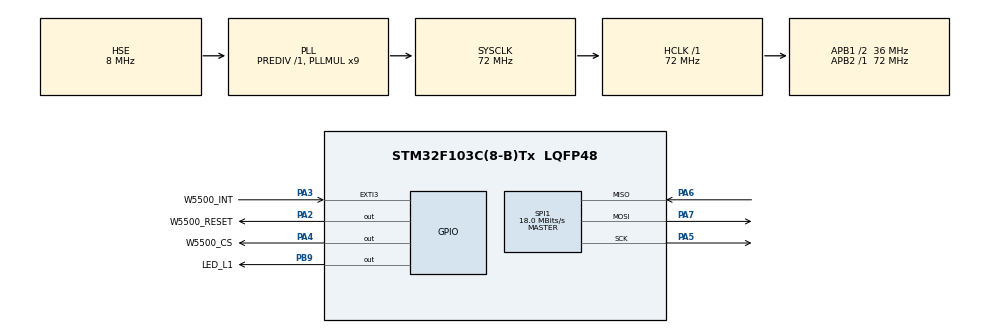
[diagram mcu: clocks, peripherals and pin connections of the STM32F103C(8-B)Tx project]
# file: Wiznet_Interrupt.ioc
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Mcu.Family=STM32F1
Mcu.Name=STM32F103C(8-B)Tx
Mcu.Package=LQFP48
NVIC.EXTI3_IRQn=true\:0\:0\:false\:false\:true\:true\:true\:true
NVIC.PriorityGroup=NVIC_PRIORITYGROUP_4
NVIC.SPI1_IRQn=true\:0\:0\:false\:false\:true\:true\:true\:true
PA13.Mode=Serial_Wire
PA13.Signal=SYS_JTMS-SWDIO
PA14.Mode=Serial_Wire
PA14.Signal=SYS_JTCK-SWCLK
PA2.GPIO_Label=W5500_RESET
PA2.Signal=GPIO_Output
PA3.GPIO_Label=W5500_INT
PA3.GPIO_ModeDefaultEXTI=GPIO_MODE_IT_FALLING
PA3.GPIO_PuPd=GPIO_PULLUP
PA3.Signal=GPXTI3
PA4.GPIO_Label=W5500_CS
PA4.Signal=GPIO_Output
PA5.Mode=Full_Duplex_Master
PA5.Signal=SPI1_SCK
PA6.Mode=Full_Duplex_Master
PA6.Signal=SPI1_MISO
PA7.Mode=Full_Duplex_Master
PA7.Signal=SPI1_MOSI
PB9.GPIO_Label=LED_L1
PB9.PinState=GPIO_PIN_SET
PB9.Signal=GPIO_Output
PD0-OSC_IN.Mode=HSE-External-Oscillator
PD0-OSC_IN.Signal=RCC_OSC_IN
PD1-OSC_OUT.Mode=HSE-External-Oscillator
PD1-OSC_OUT.Signal=RCC_OSC_OUT
ProjectManager.HeapSize=0x200
ProjectManager.StackSize=0x400
ProjectManager.TargetToolchain=STM32CubeIDE
RCC.AHBFreq_Value=72000000
RCC.APB1CLKDivider=RCC_HCLK_DIV2
RCC.APB1Freq_Value=36000000
RCC.APB1TimFreq_Value=72000000
RCC.APB2Freq_Value=72000000
RCC.APB2TimFreq_Value=72000000
RCC.HCLKFreq_Value=72000000
RCC.PLLMUL=RCC_PLL_MUL9
RCC.PLLSourceVirtual=RCC_PLLSOURCE_HSE
RCC.SYSCLKFreq_VALUE=72000000
RCC.SYSCLKSource=RCC_SYSCLKSOURCE_PLLCLK
RCC.USBFreq_Value=48000000
RCC.USBPrescaler=RCC_USBCLKSOURCE_PLL_DIV1_5
SPI1.BaudRatePrescaler=SPI_BAUDRATEPRESCALER_4
SPI1.CalculateBaudRate=18.0 MBits/s
SPI1.Direction=SPI_DIRECTION_2LINES
SPI1.Mode=SPI_MODE_MASTER
SPI1.VirtualType=VM_MASTER
board=custom

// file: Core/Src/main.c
/* USER CODE BEGIN Header */
/**
  ******************************************************************************
  * @file           : main.c
  * @brief          : Main program body
  ******************************************************************************
  * @attention
  *
  * Copyright (c) 2025 STMicroelectronics.
  * All rights reserved.
  *
  * This software is licensed under terms that can be found in the LICENSE file
  * in the root directory of this software component.
  * If no LICENSE file comes with this software, it is provided AS-IS.
  *
  ******************************************************************************
  */
/* USER CODE END Header */
#include "main.h"

SPI_HandleTypeDef hspi1;

/* USER CODE BEGIN PV */
//char sendBuffer[128];// Data holder
wiz_NetInfo netInfo = { .mac = { 0x00, 0x08, 0xdc, 0xab, 0xcd, 0xef }, .ip = {
	  		192, 168, 20, 14 }, .sn = { 255, 255, 255, 0 }, .gw = { 192, 168, 20, 1 },
	  		.dns = { 8, 8, 8, 8 }, .dhcp = NETINFO_STATIC };
uint8_t rrr = 0;
/* USER CODE END PV */

void SystemClock_Config(void);
static void MX_GPIO_Init(void);
static void MX_SPI1_Init(void);

int main(void)
{

  /* MCU Configuration--------------------------------------------------------*/

  /* Reset of all peripherals, Initializes the Flash interface and the Systick. */
  HAL_Init();

  /* Configure the system clock */
  SystemClock_Config();

  /* Initialize all configured peripherals */
  MX_GPIO_Init();
  MX_SPI1_Init();
  /* USER CODE BEGIN 2 */
//  HAL_GPIO_WritePin(LED_L1_GPIO_Port, LED_L1_Pin, SET);
  W5500Init();

  /* USER CODE END 2 */

  /* Infinite loop */
  /* USER CODE BEGIN WHILE */
  while (1)
  {

		W5500_Handle_Events();
//1
		// Send Data to PC
//		for (int socket_no = 0; socket_no < MAX_SOCK_NUM; socket_no++){
//		const char* message1 = "Hello World\r\n";
////		send(socket_no, (uint8_t*)message1, strlen(message1));
//		SendToSocket(socket_no, message1);
//		HAL_Delay(100);
//		}
//2
//		for (int socket_no = 0; socket_no < MAX_SOCK_NUM; socket_no++){
//		// Receive Data from PC and confirm the received Data by sending another message to PC
//		if (strncmp((char*)recv_buf[socket_no], "Hello", 5) == 0) {
//			memset(&recv_buf[socket_no], 0, sizeof(recv_buf[socket_no]));
////			const char* message2 = "Received\r\n";
////			send(socket_no, (uint8_t*)message2, strlen(message2));
//
//			snprintf(sendBuffer, sizeof(sendBuffer), "Received from %d\r\n", socket_no);
//			 send(socket_no, (uint8_t*)sendBuffer, strlen(sendBuffer));
//			HAL_GPIO_TogglePin(LED_L1_GPIO_Port, LED_L1_Pin);
//		}
//		}

//3

//		if (strncmp((char*)recv_buf[0], "Hello", 5) == 0) {
//			memset(&recv_buf[0], 0, sizeof(recv_buf[0]));
//			const char* message2 = "Received\r\n";
////			rrr = send(0, (uint8_t*)message2, strlen(message2));
//
////			SendToSocket(0, message2);
//			HAL_GPIO_TogglePin(LED_L1_GPIO_Port, LED_L1_Pin);
//		}

//	  HAL_Delay(1000);
}

    /* USER CODE END WHILE */

}

void SystemClock_Config(void)
{
  RCC_OscInitTypeDef RCC_OscInitStruct = {0};
  RCC_ClkInitTypeDef RCC_ClkInitStruct = {0};

  /** Initializes the RCC Oscillators according to the specified parameters
  * in the RCC_OscInitTypeDef structure.
  */
  RCC_OscInitStruct.OscillatorType = RCC_OSCILLATORTYPE_HSE;
  RCC_OscInitStruct.HSEState = RCC_HSE_ON;
  RCC_OscInitStruct.HSEPredivValue = RCC_HSE_PREDIV_DIV1;
  RCC_OscInitStruct.HSIState = RCC_HSI_ON;
  RCC_OscInitStruct.PLL.PLLState = RCC_PLL_ON;
  RCC_OscInitStruct.PLL.PLLSource = RCC_PLLSOURCE_HSE;
  RCC_OscInitStruct.PLL.PLLMUL = RCC_PLL_MUL9;
  if (HAL_RCC_OscConfig(&RCC_OscInitStruct) != HAL_OK)
  {
    Error_Handler();
  }

  /** Initializes the CPU, AHB and APB buses clocks
  */
  RCC_ClkInitStruct.ClockType = RCC_CLOCKTYPE_HCLK|RCC_CLOCKTYPE_SYSCLK
                              |RCC_CLOCKTYPE_PCLK1|RCC_CLOCKTYPE_PCLK2;
  RCC_ClkInitStruct.SYSCLKSource = RCC_SYSCLKSOURCE_PLLCLK;
  RCC_ClkInitStruct.AHBCLKDivider = RCC_SYSCLK_DIV1;
  RCC_ClkInitStruct.APB1CLKDivider = RCC_HCLK_DIV2;
  RCC_ClkInitStruct.APB2CLKDivider = RCC_HCLK_DIV1;

  if (HAL_RCC_ClockConfig(&RCC_ClkInitStruct, FLASH_LATENCY_2) != HAL_OK)
  {
    Error_Handler();
  }
}

static void MX_SPI1_Init(void)
{

  /* SPI1 parameter configuration*/
  hspi1.Instance = SPI1;
  hspi1.Init.Mode = SPI_MODE_MASTER;
  hspi1.Init.Direction = SPI_DIRECTION_2LINES;
  hspi1.Init.DataSize = SPI_DATASIZE_8BIT;
  hspi1.Init.CLKPolarity = SPI_POLARITY_LOW;
  hspi1.Init.CLKPhase = SPI_PHASE_1EDGE;
  hspi1.Init.NSS = SPI_NSS_SOFT;
  hspi1.Init.BaudRatePrescaler = SPI_BAUDRATEPRESCALER_4;
  hspi1.Init.FirstBit = SPI_FIRSTBIT_MSB;
  hspi1.Init.TIMode = SPI_TIMODE_DISABLE;
  hspi1.Init.CRCCalculation = SPI_CRCCALCULATION_DISABLE;
  hspi1.Init.CRCPolynomial = 10;
  if (HAL_SPI_Init(&hspi1) != HAL_OK)
  {
    Error_Handler();
  }

}

static void MX_GPIO_Init(void)
{
  GPIO_InitTypeDef GPIO_InitStruct = {0};

  /* GPIO Ports Clock Enable */
  __HAL_RCC_GPIOD_CLK_ENABLE();
  __HAL_RCC_GPIOA_CLK_ENABLE();
  __HAL_RCC_GPIOB_CLK_ENABLE();

  /*Configure GPIO pin Output Level */
  HAL_GPIO_WritePin(GPIOA, W5500_RESET_Pin|W5500_CS_Pin, GPIO_PIN_RESET);

  /*Configure GPIO pin Output Level */
  HAL_GPIO_WritePin(LED_L1_GPIO_Port, LED_L1_Pin, GPIO_PIN_SET);

  /*Configure GPIO pins : W5500_RESET_Pin W5500_CS_Pin */
  GPIO_InitStruct.Pin = W5500_RESET_Pin|W5500_CS_Pin;
  GPIO_InitStruct.Mode = GPIO_MODE_OUTPUT_PP;
  GPIO_InitStruct.Pull = GPIO_NOPULL;
  GPIO_InitStruct.Speed = GPIO_SPEED_FREQ_LOW;
  HAL_GPIO_Init(GPIOA, &GPIO_InitStruct);

  /*Configure GPIO pin : W5500_INT_Pin */
  GPIO_InitStruct.Pin = W5500_INT_Pin;
  GPIO_InitStruct.Mode = GPIO_MODE_IT_FALLING;
  GPIO_InitStruct.Pull = GPIO_PULLUP;
  HAL_GPIO_Init(W5500_INT_GPIO_Port, &GPIO_InitStruct);

  /*Configure GPIO pin : LED_L1_Pin */
  GPIO_InitStruct.Pin = LED_L1_Pin;
  GPIO_InitStruct.Mode = GPIO_MODE_OUTPUT_PP;
  GPIO_InitStruct.Pull = GPIO_NOPULL;
  GPIO_InitStruct.Speed = GPIO_SPEED_FREQ_LOW;
  HAL_GPIO_Init(LED_L1_GPIO_Port, &GPIO_InitStruct);

  /* EXTI interrupt init*/
  HAL_NVIC_SetPriority(EXTI3_IRQn, 0, 0);
  HAL_NVIC_EnableIRQ(EXTI3_IRQn);

}

void Error_Handler(void)
{
  __disable_irq();
  while (1)
  {
  }
}
